# APM32F070 register map
File version: 1.0
Registers are 32-bit, read-write, reset 0x0 unless marked. A register's access mark holds for its fields unless they carry their own. Offsets are from the block's base; lines under a group give offsets from that group; [hi:lo] are bit positions; {n}, {i} and the like mark numbered series; 'fields as' and 'values as' point back to an identical list; <NAME> marks a mode.

## Memory map
0x40000400 TMR3 size 0x400 — General-purpose-timers
0x40001000 TMR6 size 0x400 — Basic-timers
0x40001400 TMR7 size 0x400
0x40002000 TMR14 size 0x400 — General-purpose-timers
0x40002800 RTC size 0x400 — Real-time clock
0x40002C00 WWDT size 0x400 — Window watchdog
0x40003000 IWDT size 0x400 — Independent watchdog
0x40003800 SPI2 size 0x400
0x40004400 USART2 size 0x400
0x40004800 USART3 size 0x400
0x40004C00 USART4 size 0x400
0x40005400 I2C1 size 0x400 — Inter-integrated circuit
0x40005800 I2C2 size 0x400
0x40005C00 USBD size 0x800 — Universal Serial BuswFull-SpeedDevice
0x40007000 PMU size 0x400 — Power control
0x40010000 SYSCFG size 0x400 — System configuration controller
0x40010400 EINT size 0x400 — External interrupt/event controller
0x40012400 ADC size 0x400 — Analog-to-digital converter
0x40012C00 TMR1 size 0x400 — Advanced-timers
0x40013000 SPI1 size 0x400 — Serial peripheral interface
0x40013800 USART1 size 0x400 — Universal synchronous asynchronous receiver transmitter
0x40014000 TMR15 size 0x400 — General-purpose-timers
0x40014400 TMR16 size 0x400 — General-purpose-timers
0x40014800 TMR17 size 0x400
0x40015800 DBG size 0x400 — Debug support
0x40020000 DMA size 0x400 — DMA controller
0x40021000 RCM size 0x400 — Reset and clock control
0x40022000 FMC size 0x400 — Flash
0x40023000 CRC size 0x400 — cyclic redundancy check calculation unit
0x48000000 GPIOA size 0x400 — General-purpose I/Os
0x48000400 GPIOB size 0x400
0x48000800 GPIOC size 0x400
0x48000C00 GPIOD size 0x400
0x48001000 GPIOE size 0x400
0x48001400 GPIOF size 0x400 — General-purpose I/Os
0xE000E100 NVIC size 0x33D — Nested Vectored Interrupt Controller

## Interrupts
0 WWDT — Window Watchdog interrupt
1 PVD (EINT) — PVD interrupt
2 RTC — RTC interrupts
3 FLASH (FMC) — FLASH global Interrupt
4 RCM — RCC global interrupts
5 EINT0_1 (EINT) — EINT Line[1:0] interrupts
6 EINT2_3 (EINT) — EINT Line[3:2] interrupts
7 EINT4_15 (EINT) — EINT Line15 and EINT4 interrupts
9 DMA1_CH1 (DMA) — DMA1 channel 1 interrupt
10 DMA1_CH2_3 (DMA) — DMA1 channel 2 and 3 interrupts
11 DMA1_CH4_5 (DMA) — DMA1 channel 4, 5 interrupts
12 ADC1 (ADC) — ADC interrupts
13 TMR1_BRK_UP_TRG_COM (TMR1) — TMR1 Break, Update, Trigger and Commutation Interrupt
14 TMR1_CC (TMR1) — TMR1 Capture Compare Interrupt
16 TMR3 — TMR3 global interrupt
17 TMR6 — TMR6 global interrupt
18 TMR7 — TMR7 global interrupt
19 TMR14 — TMR14 global Interrupt
20 TMR15 — TMR15 global Interrupt
21 TMR16 — TMR16 global Interrupt
22 TMR17 — TMR17 global Interrupt
23 I2C1 — I2C1 global interrupt
24 I2C2 — I2C2 global interrupt
25 SPI1 — SPI1_global_interrupt
26 SPI2 — SPI2 global interrupt
27 USART1 — USART1 global interrupt
28 USART2 — USART2 global interrupt
29 USART3_4 (USART3, USART4) — USART3 and USART4 global interrupt
31 USBD — USB interrupts

## CRC — cyclic redundancy check calculation unit
Base 0x40023000
0x00 DATA reset 0xFFFFFFFF
  [31:0] DATA — Data register bits
0x04 INDATA — Independent data register
  [7:0] INDATA — General-purpose 8-bit data register bits
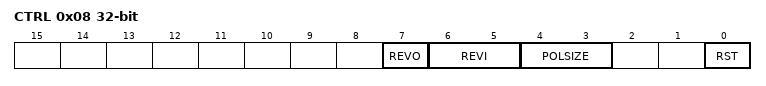
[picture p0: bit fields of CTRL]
0x08 CTRL — Control register
  [7] REVO — Reverse output data
  [6:5] REVI — Reverse input data
  [4:3] POLSIZE — Polynomial size
  [0] RST — reset bit
0x10 INITVAL reset 0xFFFFFFFF — Initial CRC value
  [31:0] VALUE — Programmable initial CRC value
0x14 POL reset 0x4C11DB7 — Programmable polynomial
  [31:0] PPOL

## GPIOF — General-purpose I/Os
Base 0x48001400
Same registers: GPIOB 0x48000400, GPIOC 0x48000800, GPIOD 0x48000C00, GPIOE 0x48001000
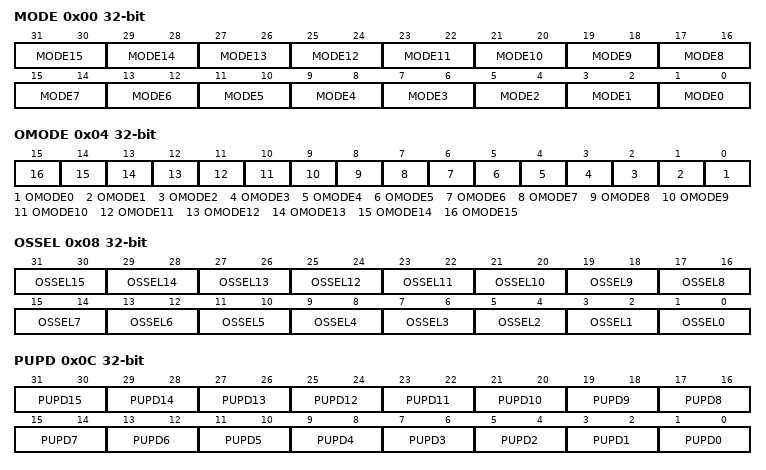
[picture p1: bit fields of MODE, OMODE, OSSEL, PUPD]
0x00 MODE — GPIO port mode register
  [2n+1:2n] MODE{n} (n=0..15) — Port x configuration bits (y = 0..15)
0x04 OMODE — GPIO port output type register
  [n] OMODE{n} (n=0..15) — Port x configuration bit {n}
0x08 OSSEL — GPIO port output speed register
  [2n+1:2n] OSSEL{n} (n=0..15) — Port x configuration bits (y = 0..15)
0x0C PUPD — GPIO port pull-up/pull-down register
  [2n+1:2n] PUPD{n} (n=0..15) — Port x configuration bits (y = 0..15)
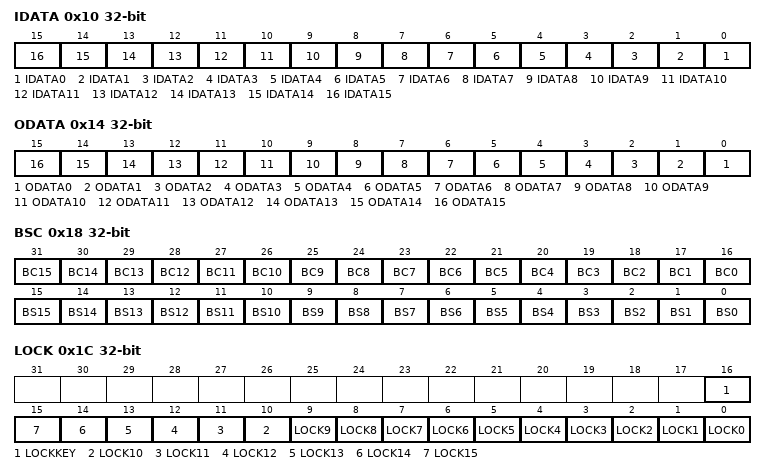
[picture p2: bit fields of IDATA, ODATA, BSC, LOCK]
0x10 IDATA ro — GPIO port input data register
  [n] IDATA{n} (n=0..15) — Port input data (y = 0..15)
0x14 ODATA — GPIO port output data register
  [n] ODATA{n} (n=0..15) — Port output data (y = 0..15)
0x18 BSC wo — GPIO port bit set/clear register
  [n+16] BC{n} (n=1..15) — Port x clear bit y (y = 0..15)
  [16] BC0 — Port x set bit y ( y = 0..15)
  [n] BS{n} (n=9..15) — Port x set bit y ( y = 0..15)
  [n] BS{n} (n=0..8) — Port x set bit y (y = 0..15)
0x1C LOCK — GPIO port configuration lock register
  [16] LOCKKEY — Port x lock bit y
  [n] LOCK{n} (n=0..15) — Port x lock bit y (y = 0..15)
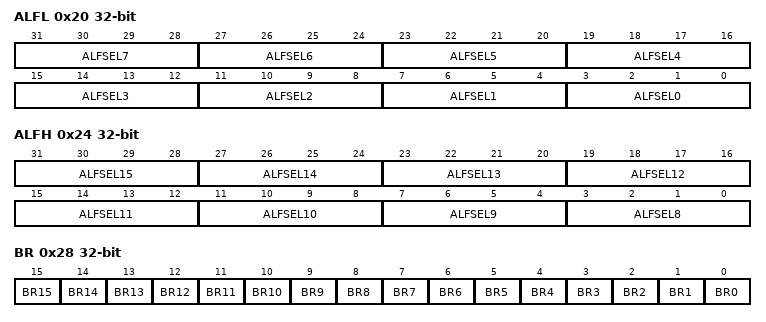
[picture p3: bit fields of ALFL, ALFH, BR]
0x20 ALFL — GPIO alternate function low register
  [4n+3:4n] ALFSEL{n} (n=0..7) — Alternate function selection for port xbit y (y = 0..7)
0x24 ALFH — GPIO alternate function high register
  [4n-29:4n-32] ALFSEL{n} (n=11..15) — Alternate function selection for port xbit y (y = 8..15)
  [11:8] ALFSEL10 — Alternate function selection for port x bit y (y = 8..15)
  [7:4] ALFSEL9 — Alternate function selection for port x bit y (y = 8..15)
  [3:0] ALFSEL8 — Alternate function selection for port x bit y (y = 8..15)
0x28 BR wo — Port bit clear register
  [n] BR{n} (n=0..15) — Port x clear bit y
